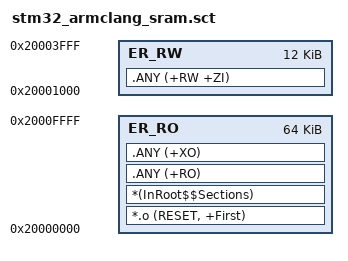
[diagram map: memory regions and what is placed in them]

LR 0x20000000 0x00010000  {       ; load region size_region
  ER_RO 0x20000000 0x00010000  {  ; load address = execution address
   *.o (RESET, +First)
   *(InRoot$$Sections)
   .ANY (+RO)
   .ANY (+XO)
  }
  ER_RW 0x20001000 0x00003000  {  ; RW data
   .ANY (+RW +ZI)
  }
}
